# STM32G554xx register map
File version: 1.0
Registers are 32-bit, read-write, reset 0x0 unless marked. A register's access mark holds for its fields unless they carry their own. Offsets are from the block's base; [hi:lo] are bit positions; {n}, {i} and the like mark numbered series.

## I3C1 — Improved inter-integrated circuit (I3C)
Base 0x40005C00
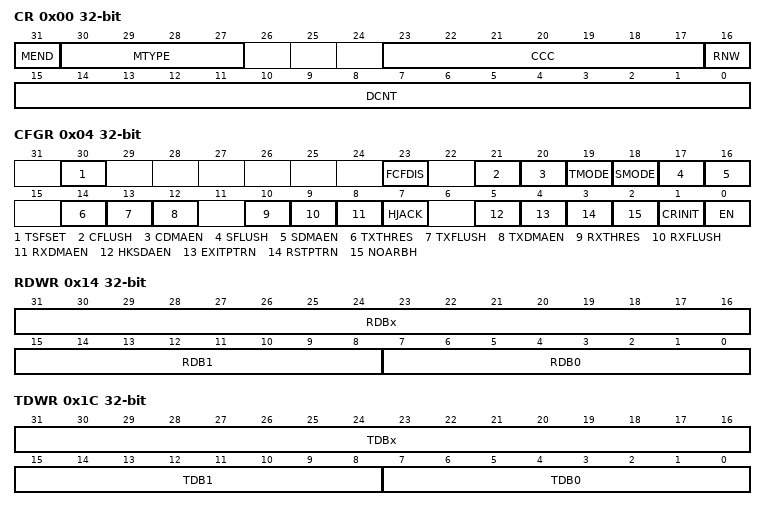
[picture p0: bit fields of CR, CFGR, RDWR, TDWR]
0x00 CR — I3C message control register
  [31] MEND, [30:27] MTYPE, [23:17] CCC, [16] RNW, [15:0] DCNT
0x04 CFGR — I3C configuration register
  [30] TSFSET
  [23] FCFDIS
  [21] CFLUSH
  [20] CDMAEN
  [19] TMODE
  [18] SMODE
  [17] SFLUSH
  [16] SDMAEN
  [14] TXTHRES
  [13] TXFLUSH
  [12] TXDMAEN
  [10] RXTHRES
  [9] RXFLUSH
  [8] RXDMAEN
  [7] HJACK
  [5] HKSDAEN
  [4] EXITPTRN
  [3] RSTPTRN
  [2] NOARBH
  [1] CRINIT — Initial controller/target role
  [0] EN
0x10 RDR ro — I3C receive data byte register
  [7:0] RDB0 — 8-bit received data on I3C bus
0x14 RDWR ro — I3C receive data word register
  [31:16] RDBx — Receive Data Byte, full double word
  [15:8] RDB1
  [7:0] RDB0
0x18 TDR — I3C transmit data byte register
  [7:0] TDB0 — 8-bit data to transmit on I3C bus
0x1C TDWR — I3C transmit data word register
  [31:16] TDBx — Transmit Data Byte, full double word
  [15:8] TDB1
  [7:0] TDB0
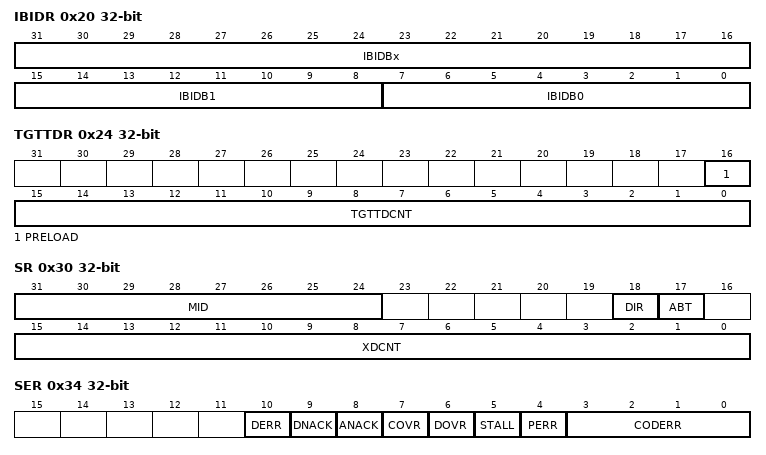
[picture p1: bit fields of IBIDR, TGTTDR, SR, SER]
0x20 IBIDR — I3C IBI payload data register
  [31:16] IBIDBx — IBI Data Byte, full double word
  [15:8] IBIDB1
  [7:0] IBIDB0
0x24 TGTTDR — I3C target transmit configuration register
  [16] PRELOAD, [15:0] TGTTDCNT
0x30 SR ro — I3C status register
  [31:24] MID
  [18] DIR — Message direction
  [17] ABT
  [15:0] XDCNT — Data counter
0x34 SER ro — I3C status error register
  [10] DERR
  [9] DNACK
  [8] ANACK
  [7] COVR
  [6] DOVR — RX-FIFO overrun or TX-FIFO underrun
  [5] STALL
  [4] PERR — Protocol error
  [3:0] CODERR — Protocol error code/type
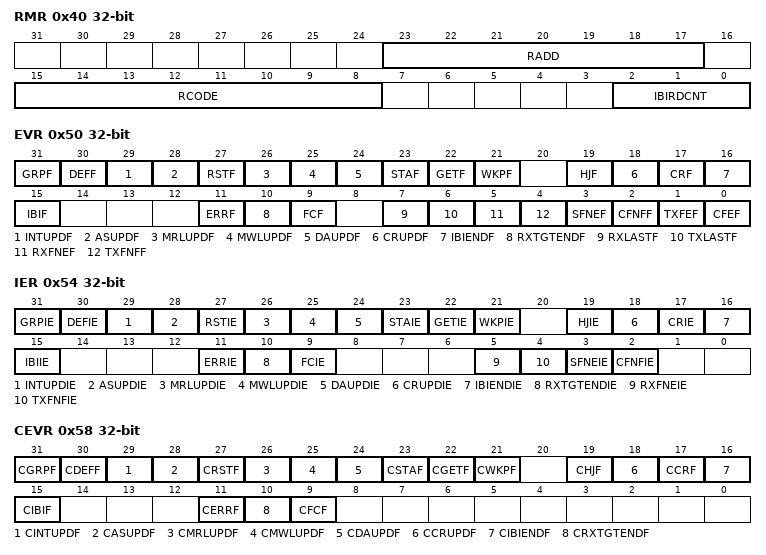
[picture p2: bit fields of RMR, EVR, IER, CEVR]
0x40 RMR ro — I3C received message register
  [23:17] RADD, [15:8] RCODE, [2:0] IBIRDCNT
0x50 EVR ro — I3C event register
  [31] GRPF
  [30] DEFF
  [29] INTUPDF
  [28] ASUPDF
  [27] RSTF
  [26] MRLUPDF
  [25] MWLUPDF
  [24] DAUPDF
  [23] STAF
  [22] GETF — Get flag (when the I3C acts as target)
  [21] WKPF
  [19] HJF
  [18] CRUPDF
  [17] CRF
  [16] IBIENDF
  [15] IBIF
  [11] ERRF
  [10] RXTGTENDF
  [9] FCF
  [7] RXLASTF
  [6] TXLASTF
  [5] RXFNEF
  [4] TXFNFF
  [3] SFNEF
  [2] CFNFF
  [1] TXFEF
  [0] CFEF
0x54 IER — I3C interrupt enable register
  [31] GRPIE, [30] DEFIE, [29] INTUPDIE, [28] ASUPDIE, [27] RSTIE, [26] MRLUPDIE, [25] MWLUPDIE, [24] DAUPDIE, [23] STAIE, [22] GETIE, [21] WKPIE, [19] HJIE, [18] CRUPDIE, [17] CRIE, [16] IBIENDIE, [15] IBIIE, [11] ERRIE, [10] RXTGTENDIE, [9] FCIE, [5] RXFNEIE, [4] TXFNFIE, [3] SFNEIE, [2] CFNFIE
0x58 CEVR — I3C clear event register
  [31] CGRPF, [30] CDEFF, [29] CINTUPDF, [28] CASUPDF, [27] CRSTF, [26] CMRLUPDF, [25] CMWLUPDF, [24] CDAUPDF, [23] CSTAF, [22] CGETF, [21] CWKPF, [19] CHJF, [18] CCRUPDF, [17] CCRF, [16] CIBIENDF, [15] CIBIF, [11] CERRF, [10] CRXTGTENDF, [9] CFCF
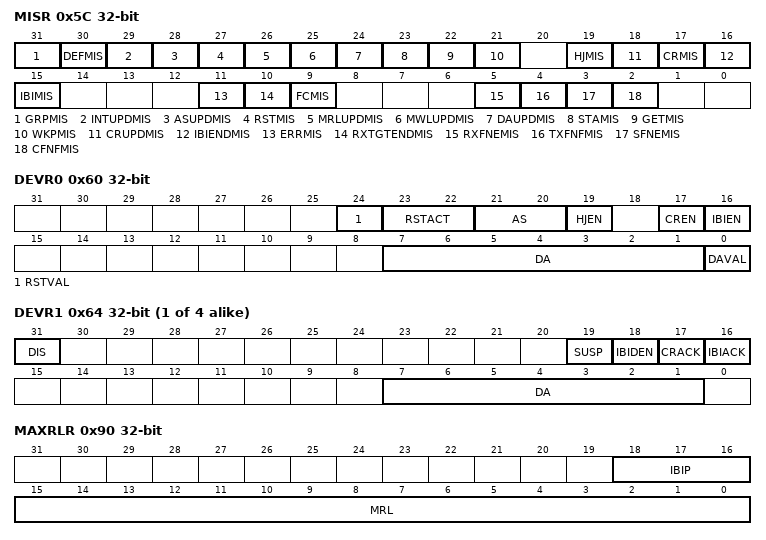
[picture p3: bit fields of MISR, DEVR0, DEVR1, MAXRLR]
0x5C MISR ro — I3C masked interrupt status register
  [31] GRPMIS, [30] DEFMIS, [29] INTUPDMIS, [28] ASUPDMIS, [27] RSTMIS, [26] MRLUPDMIS, [25] MWLUPDMIS, [24] DAUPDMIS, [23] STAMIS, [22] GETMIS, [21] WKPMIS, [19] HJMIS, [18] CRUPDMIS, [17] CRMIS, [16] IBIENDMIS, [15] IBIMIS, [11] ERRMIS, [10] RXTGTENDMIS, [9] FCMIS, [5] RXFNEMIS, [4] TXFNFMIS, [3] SFNEMIS, [2] CFNFMIS
0x60 DEVR0 — I3C own device characteristics register
  [24] RSTVAL
  [23:22] RSTACT
  [21:20] AS
  [19] HJEN
  [17] CREN
  [16] IBIEN
  [7:1] DA — 7-bit dynamic address
  [0] DAVAL
{0x60+4i} DEVR{i} (i=1..4) — I3C device 1 characteristics register
  [31] DIS, [19] SUSP, [18] IBIDEN, [17] CRACK, [16] IBIACK, [7:1] DA
0x90 MAXRLR — I3C maximum read length register
  [18:16] IBIP, [15:0] MRL
0x94 MAXWLR — I3C maximum write length register
  [15:0] MWL
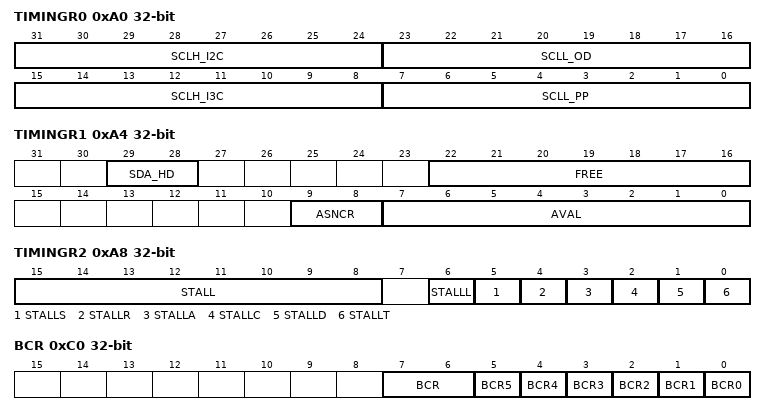
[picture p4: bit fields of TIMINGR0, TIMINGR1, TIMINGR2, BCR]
0xA0 TIMINGR0 — I3C timing register 0
  [31:24] SCLH_I2C
  [23:16] SCLL_OD — SCL low duration in open-drain phases
  [15:8] SCLH_I3C
  [7:0] SCLL_PP
0xA4 TIMINGR1 — I3C timing register 1
  [29:28] SDA_HD — SDA hold time
  [22:16] FREE
  [9:8] ASNCR
  [7:0] AVAL
0xA8 TIMINGR2 — I3C timing register 2
  [15:8] STALL, [6] STALLL, [5] STALLS, [4] STALLR, [3] STALLA, [2] STALLC, [1] STALLD, [0] STALLT
0xC0 BCR — I3C bus characteristics register
  [7:6] BCR — Bus Characteristics
  [5] BCR5 — Advanced capabilities
  [4] BCR4 — Virtual target support
  [3] BCR3 — Offline capable
  [2] BCR2 — in-band interrupt (IBI) payload
  [1] BCR1 — IBI Request capable
  [0] BCR0 — max data speed limitation
0xC4 DCR — I3C device characteristics register
  [7:0] DCR — device characteristics ID
0xC8 GETCAPR — I3C get capability register
  [14] CAPPEND
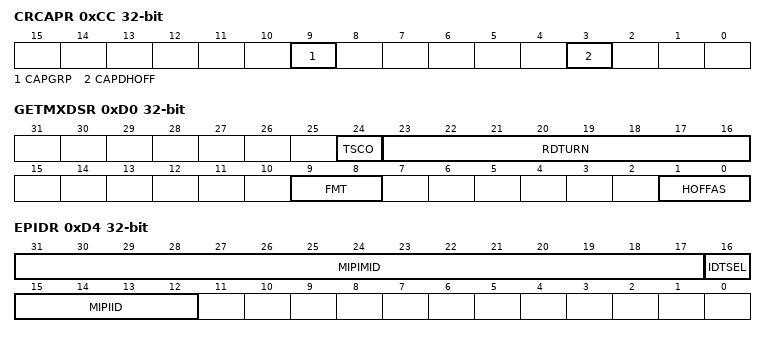
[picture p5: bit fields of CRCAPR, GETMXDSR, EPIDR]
0xCC CRCAPR — I3C controller-role capability register
  [9] CAPGRP
  [3] CAPDHOFF — delayed controller-role hand-off
0xD0 GETMXDSR — I3C get max data speed register
  [24] TSCO
  [23:16] RDTURN
  [9:8] FMT — GETMXDS CCC format
  [1:0] HOFFAS — Controller hand-off activity state
0xD4 EPIDR — I3C extended provisioned ID register
  [31:17] MIPIMID — 15-bit MIPI manufacturer ID
  [16] IDTSEL — provisioned ID type selector
  [15:12] MIPIID — 4-bit MIPI Instance ID
